# S1C31D50 register map
Vendor: Epson; Series: S1C31D50; File version: 1.00
CPU: CM0PLUS r0p1, little endian, MPU, no FPU, VTOR, 2 interrupt priority bits
Registers are 16-bit, read-write, reset 0x0 unless marked. A register's access mark holds for its fields unless they carry their own. Offsets are from the block's base; [hi:lo] are bit positions.

## CLG — Clock sources control and clock supply management
Base 0x00200040
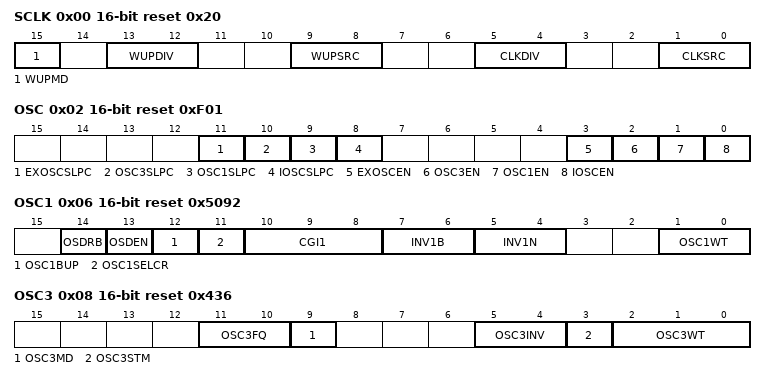
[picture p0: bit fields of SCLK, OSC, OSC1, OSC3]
0x00 SCLK reset 0x20 — System Clock Control Register
  [15] WUPMD — Wakeup mode select (can be write protected)
    0=SAME_SRC (Same source); 1=SEL_SRC (Selected source)
  [13:12] WUPDIV — Wakeup system clock division ratio select (can be write protected)
  [9:8] WUPSRC — Wakeup system clock source select (can be write protected)
    0=IOSC; 1=OSC1; 2=OSC3; 3=EXOSC
  [5:4] CLKDIV — System clock division ratio select (can be write protected)
  [1:0] CLKSRC — System clock source select (can be write protected)
    0=IOSC; 1=OSC1; 2=OSC3; 3=EXOSC
0x02 OSC reset 0xF01 — Oscillation Control Register
  [all] fields
    0=DISABLE; 1=ENABLE
  [11] EXOSCSLPC — EXOSC clock sleep control (can be write protected)
  [10] OSC3SLPC — OSC3 clock sleep control
  [9] OSC1SLPC — OSC1 clock sleep control
  [8] IOSCSLPC — IOSC clock sleep control
  [3] EXOSCEN — EXOSC enable
  [2] OSC3EN — OSC3 enable
  [1] OSC1EN — OSC1 enable
  [0] IOSCEN — IOSC enable
0x04 IOSC reset 0x2 — IOSC Control Register
  [1:0] IOSCFQ — IOSC frequency select (can be write protected)
    0=1MHZ; 1=2MHZ; 2=8MHZ; 3=8MHZ
0x06 OSC1 reset 0x5092 — OSC1 Control Register
  [14] OSDRB — OSC stop reboot enable (can be write protected)
    0=DISABLE; 1=ENABLE
  [13] OSDEN — OSC stop detector enable (can be write protected)
    0=DISABLE; 1=ENABLE
  [12] OSC1BUP — OSC boost-up boot enable (can be write protected)
    0=DISABLE; 1=ENABLE
  [11] OSC1SELCR — OSC oscillator select (can be write protected)
    0=CRYSTAL; 1=INTERNAL
  [10:8] CGI1 — Gate capacitance select (can be write protected)
    0=0PF (0pF+(5pF)); 1=2PF (2pF+(5pF)); 2=4PF (4pF+(5pF)); 3=6PF (6pF+(5pF)); 4=8PF (8pF+(5pF)); 5=10PF (10pF+(5pF)); 6=12PF (12pF+(5pF)); 7=14PF (14pF+(5pF))
  [7:6] INV1B — Boot OSC inverter select (can be write protected)
  [5:4] INV1N — Normal OSC inverter select (can be write protected)
  [1:0] OSC1WT — OSC1 wait cycle select (can be write protected)
    0=1_CLK (1 clock (reserved)); 1=4096_CLK (4096 clocks); 2=16384_CLK (16384 clocks); 3=65536_CLK (65536 clocks)
0x08 OSC3 reset 0x436 — OSC3 Control Register
  [11:10] OSC3FQ — OSC3 CR(Int)mode frequency select(can be write protected)
    0=4MHz; 1=8MHz; 2=12MHz; 3=16MHz
  [9] OSC3MD — OSC3 mode select (can be write protected)
    0=CR(Int); 1=XTAL
  [5:4] OSC3INV — OSC3 X'tal mode inverter select (can be write protected)
  [3] OSC3STM — OSC3 self trimming enable (can be write protected)
    on write: 0=TRIM_STOP (Stop trimming); 1=TRIM_START (Start trimming) | on read: 0=STOPPED (Trimming has finished); 1=RUNNING (Trimming is executing)
  [2:0] OSC3WT — OSC3 wait cycle select (can be write protected)
    0=4_CLK (4 clocks); 1=16_CLK (16 clocks); 2=64_CLK (64 clocks); 3=256_CLK (256 clocks); 4=1024_CLK (1024 clocks); 5=4096_CLK (4096 clocks); 6=16384_CLK (16384 clocks); 7=65536_CLK (65536 clocks)
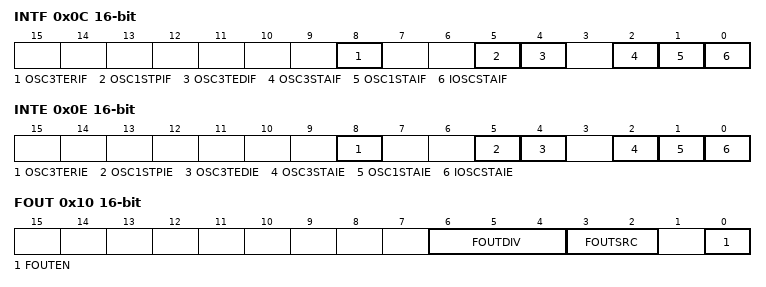
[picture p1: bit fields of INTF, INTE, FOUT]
0x0C INTF — Interrupt Flag Register
  [all] fields
    0=NOT_OCCURED (No cause of interrupt occurred); 1=OCCURED (Cause of interrupt occurred)
  [8] OSC3TERIF write-1-clears — OSC3 trimming error interrupt flag
  [5] OSC1STPIF write-1-clears — OSC1 oscillation stop interrupt flag
  [4] OSC3TEDIF write-1-clears — OSC3 trimming end interrupt flag
  [2] OSC3STAIF write-1-clears — OSC3 oscillation stable interrupt flag
  [1] OSC1STAIF write-1-clears — OSC1 oscillation stable interrupt flag
  [0] IOSCSTAIF write-1-clears — IOSC oscillation stable interrupt flag
0x0E INTE — Interrupt Enable Register
  [all] fields
    0=DISABLE; 1=ENABLE
  [8] OSC3TERIE — OSC3 trimming error interrupt enable
  [5] OSC1STPIE — OSC1 oscillation stop interrupt enable
  [4] OSC3TEDIE — OSC3 trimming end interrupt enable
  [2] OSC3STAIE — OSC3 oscillation stable interrupt enable
  [1] OSC1STAIE — OSC1 oscillation stable interrupt enable
  [0] IOSCSTAIE — IOSC oscillation stable interrupt enable
0x10 FOUT — FOUT Control Register
  [6:4] FOUTDIV — FOUT clock division ratio select
  [3:2] FOUTSRC — FOUTA clock source select
    0=IOSC; 1=OSC1; 2=OSC3; 3=SYSCLK (SYSTEM CLK)
  [0] FOUTEN — FOUTA output enable
    0=DISABLE; 1=ENABLE
